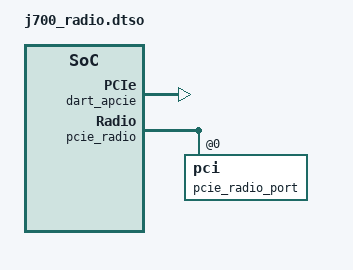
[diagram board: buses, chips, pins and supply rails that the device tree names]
// SPDX-License-Identifier: GPL-2.0-only
/dts-v1/;
/plugin/;

/ {
	fragment@0 {
		target-path = "/soc";

		__overlay__ {
			dart_apcie: iommu@390000000 {
				compatible = "apple,t8140-dart", "apple,t8110-dart";
				reg = <0x3 0x90000000 0x0 0x20000>;
				#iommu-cells = <1>;
				interrupt-parent = <0x9>;
				interrupts = <0x0 0x4b6 0x4>;
				power-domains = <0x7002>;
				apple,force-available;
			};

			piodma_radio: piodma@390030000 {
				compatible = "apple,t8140-pcie-piodma";
				reg = <0x3 0x90030000 0x0 0x4000
				       0x3 0x90034000 0x0 0x4000
				       0x3 0x90038000 0x0 0x4000>;
				reg-names = "engine", "irq-aggregator", "fabric";
				interrupt-parent = <0x9>;
				interrupts = <0x0 0x4b7 0x4>;
				iommus = <&dart_apcie 17>;
				apple,iova-address-bits = <36>;
				apple,piodma-base-addresses =
					<0x1c 0xb0000000>, <0xb 0xc0000000>,
					<0xb 0x80000000>;
				apple,piodma-aperture-sizes =
					<0x0 0x10000000>, <0x0 0x20000000>,
					<0x0 0x40000000>;
			};

			pcie_radio: pcie@1cb0000000 {
				compatible = "apple,t8140-pcie", "apple,t6020-pcie";
				device_type = "pci";
				reg = <0x1c 0xb0000000 0x0 0x10000000
				       0x3 0x94000000 0x0 0x4000
				       0x3 0x90028000 0x0 0x8000
				       0x3 0x97020000 0x0 0x4000>;
				reg-names = "config", "rc", "port0", "phy0";
				interrupt-parent = <0x9>;
				interrupts = <0x0 0x4b5 0x4>;
				msi-controller;
				msi-parent = <&pcie_radio>;
				msi-ranges = <0x9 0x0 0x533 0x1 0x20>;
				iommu-map = <0x100 &dart_apcie 0x1 0x1
					     0x101 &dart_apcie 0x2 0x1>;
				iommu-map-mask = <0xffff>;
				bus-range = <0x0 0x8>;
				#address-cells = <3>;
				#size-cells = <2>;
				ranges = <0x43000000 0xb 0xc0000000
					  0xb 0xc0000000 0x0 0x20000000
					  0x02000000 0x0 0x80000000
					  0xb 0x80000000 0x0 0x40000000>;
				apple,valid-functions = <0x3>;
				apple,endpoint-iova-address-bits = <32>;
				dma-coherent;
				apple,piodma = <&piodma_radio>;
				power-domains = <0x7002>;

				pcie_radio_port: pci@0,0 {
					device_type = "pci";
					reg = <0x0 0x0 0x0 0x0 0x0>;
					reset-gpios = <0x1f 0x72 0x1>;
					pwren-gpios = <0x31 0x8 0x0>;
					maximum-link-speed = <2>;
					#address-cells = <3>;
					#size-cells = <2>;
					ranges;
					interrupt-controller;
					#interrupt-cells = <1>;
					interrupt-map-mask = <0x0 0x0 0x0 0x7>;
					interrupt-map = <0x0 0x0 0x0 0x1
							 &pcie_radio_port 0x0
						 0x0 0x0 0x0 0x2
							 &pcie_radio_port 0x1
						 0x0 0x0 0x0 0x3
							 &pcie_radio_port 0x2
						 0x0 0x0 0x0 0x4
							 &pcie_radio_port 0x3>;

					wifi@0,0 {
						compatible = "pci14c3,7932";
						reg = <0x10000 0x0 0x0 0x0 0x0>;
					};
				};
			};
		};
	};
};
